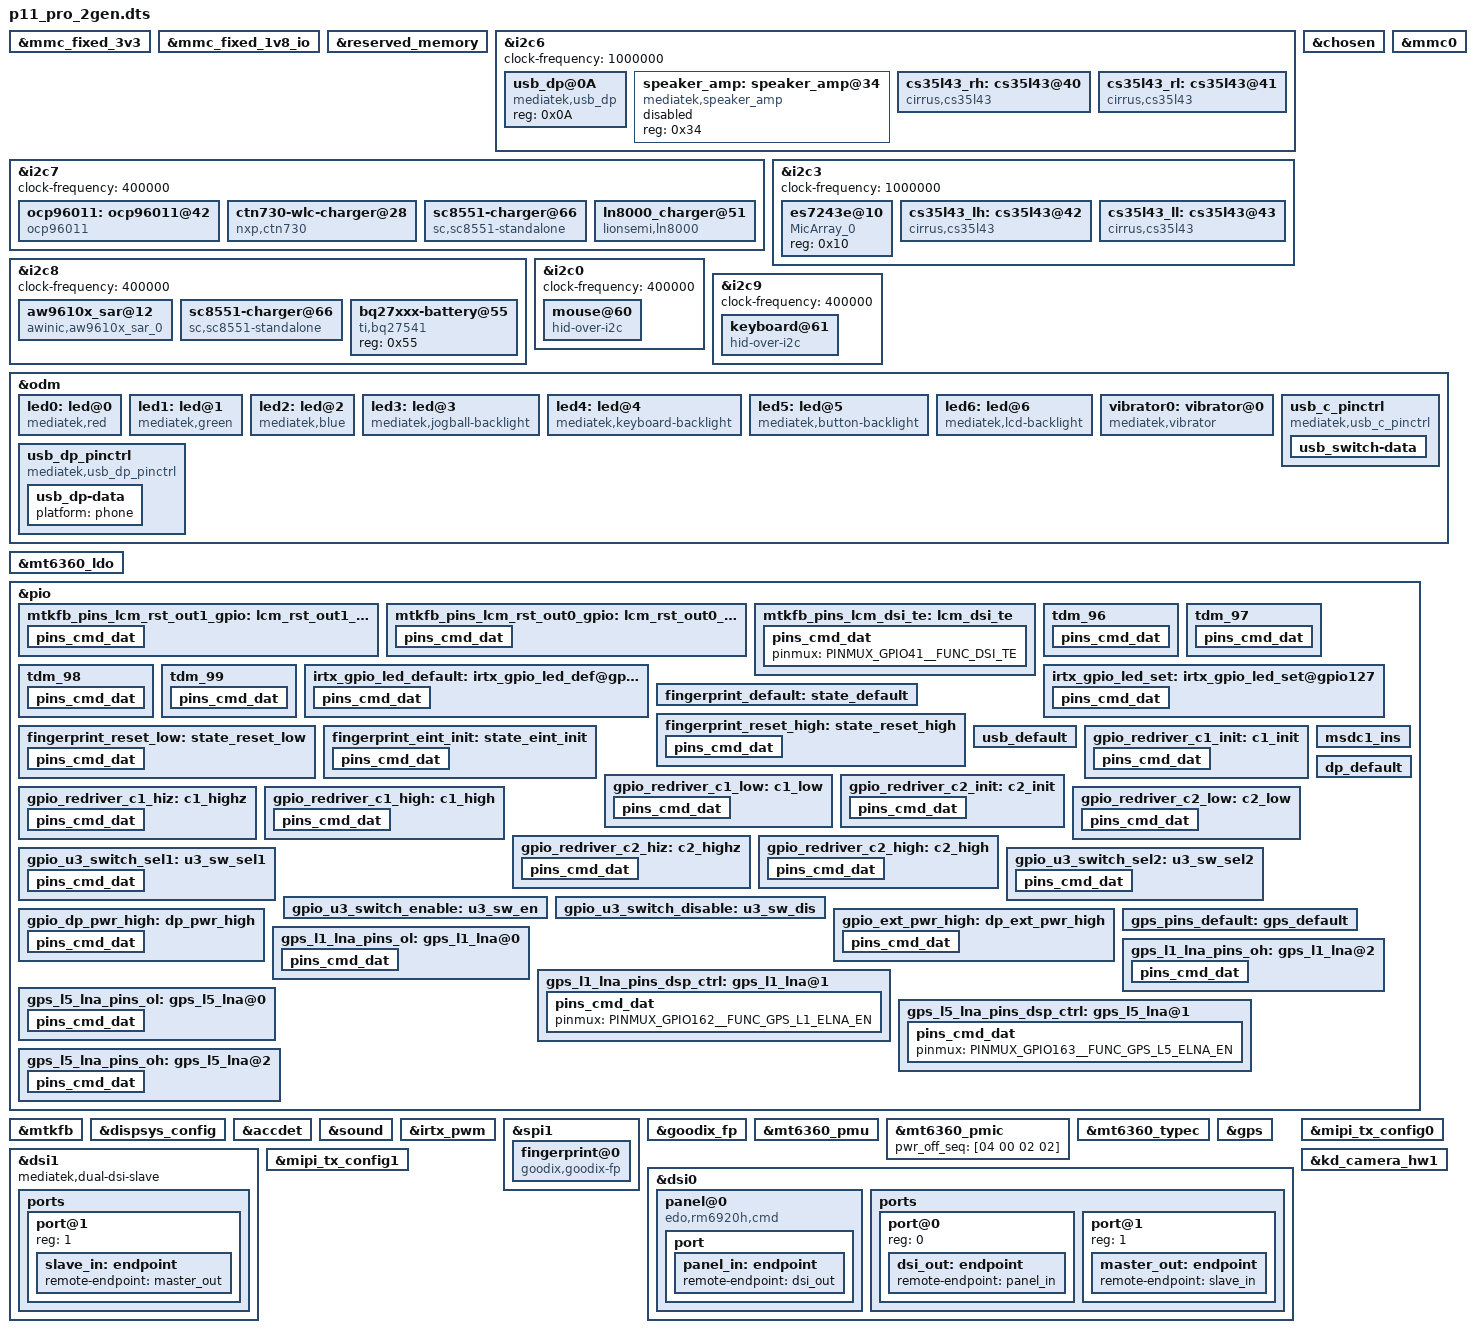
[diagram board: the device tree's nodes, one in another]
/*
 * Mediatek's mt6893 SoC device tree source
 *
 * Copyright (C) 2016 MediaTek Inc.
 *
 * This program is free software; you can redistribute it and/or modify
 * it under the terms of the GNU General Public License version 2 as
 * published by the Free Software Foundation.
 *
 * This program is distributed in the hope that it will be useful,
 * but WITHOUT ANY WARRANTY; without even the implied warranty of
 * MERCHANTABILITY or FITNESS FOR A PARTICULAR PURPOSE.
 * See http://www.gnu.org/licenses/gpl-2.0.html for more details.
 */
/dts-v1/;
/plugin/;
#include <dt-bindings/interrupt-controller/irq.h>
#include <dt-bindings/interrupt-controller/arm-gic.h>
#include <dt-bindings/spmi/spmi.h>
#include <dt-bindings/pinctrl/mt6885-pinfunc.h>

&mmc_fixed_3v3 {
	status = "okay";
	regulator-name = "mmc_power";
	regulator-min-microvolt = <3300000>;
	regulator-max-microvolt = <3300000>;
	enable-active-high;
	regulator-always-on;
};

&mmc_fixed_1v8_io {
	status = "okay";
	regulator-name = "mmc_io";
	regulator-min-microvolt = <1800000>;
	regulator-max-microvolt = <1800000>;
	enable-active-high;
	regulator-always-on;
};

&reserved_memory {
};


&i2c6 {
	clock-frequency = <400000>;
	status = "okay";

	usb_dp@0A {
	compatible = "mediatek,usb_dp";
	reg = <0x0A>;
	status = "okay";
	};
};

&i2c7 {
/*Type-C Analog Audio Switch : OCP96011*/
	ocp96011: ocp96011@42 {
	compatible = "ocp96011";
	reg = <0x42>;
	status = "okay";
	enable-gpio = <&pio 192 0x0>;
	irq-gpio = <&pio 2 0>;
	};

	ctn730-wlc-charger@28 {
	compatible = "nxp,ctn730";
	reg = <0x28>;
	interrupt-gpios = <&pio 15 0x0>;
	rst-gpios = <&pio 133 0x0>;
	boost-5v-gpios = <&pio 185 0x0>;
	enable-gpios = <&pio 193 0x0>;
	status = "okay";
	};
};

&i2c3 {
	status = "okay";
	es7243e@10 {
            compatible = "MicArray_0";
            reg = <0x10>;
	    /*vrf18_adc-supply = <&mt_pmic_vrf18_ldo_reg>;*/
            status = "okay";
    };
};

/* chosen */
&chosen {

	atag,videolfb-fb_base_l = <0x7e020000>;
	atag,videolfb-fb_base_h = <0x0>;
	atag,videolfb-islcmfound = <1>;
	atag,videolfb-islcm_inited = <0>;
	atag,videolfb-fps= <6000>;
	atag,videolfb-vramSize= <0x1be0000>;
	atag,videolfb-lcmname=
		"nt35595_fhd_dsi_cmd_truly_nt50358_drv";
};

&i2c8 {
        clock-frequency = <400000>;

	aw9610x_sar@12 {
		compatible = "awinic,aw9610x_sar_0";
		reg = <0x12>;
		irq-gpio = <&pio 6 0x0>;
		chip_name = "AW96105";
		aw9610x,using-firmware;
		sar-num = < 0 >;
		channel_config = < 1 0 1 0 1>;
		status = "okay";
	};

	sc8551-charger@66{
		compatible = "sc,sc8551-standalone";
		reg = <0x66>;
		sc,sc8551,interrupt_gpios = <&pio 11 0>;
		/*
		sc,sc8551,bat-ovp-disable = <0>;
		sc,sc8551,bat-ocp_disable = <0>;
		sc,sc8551,bat-ovp-alarm-disable = <0>;
		sc,sc8551,bus-ocp-disable = <0>;
		sc,sc8551,bus-ovp-alarm-disable = <0>;
		sc,sc8551,bus-ocp-alarm-disable = <0>;
		sc,sc8551,bat-ucp-alarm-disable = <0>;
		*/
		sc,sc8551,bat-therm-disable = <0>;
		sc,sc8551,bus-therm-disable = <0>;

		sc,sc8551,bat-ovp-threshold = <4500>;
		sc,sc8551,bat-ovp-alarm-threshold = <4450>;
		sc,sc8551,bat-ocp-threshold = <6500>;
		sc,sc8551,bat-ocp-alarm-threshold = <6200>;

		sc,sc8551,bus-ovp-threshold = <12000>;
		sc,sc8551,bus-ovp-alarm-threshold = <11000>;
		sc,sc8551,bus-ocp-threshold = <3500>;
		sc,sc8551,bus-ocp-alarm-threshold = <3200>;

		sc,sc8551,bat-ucp-alarm-threshold = <2000>;

		sc,sc8551,bat-therm-threshold = <0x15>;
		sc,sc8551,bus-therm-threshold = <0x15>;
		sc,sc8551,die-therm-threshold = <125>;

		sc,sc8551,ac-ovp-threshold = <17>;
		sc,sc8551,sense-resistor-mohm = <5>;
	};

	bq27xxx-battery@55 {
		compatible = "ti,bq27541";
		reg = <0x55>;
		status = "okay";
	};
};

&i2c0 {
       //clock-frequency = <1000000>;
	clock-frequency = <400000>;
	status = "okay";
	//as33970@41 {

	//compatible = "syna,as33970";

	mouse@60 {
	compatible = "hid-over-i2c";
	reg = <0x60>;
	vfp-supply = <&mt_pmic_vfp_ldo_reg>;
	mcu_en_gpio = <&pio 185 0>;
	mcu_rst_gpio = <&pio 147 0>;
	mcu_hall_int_gpio = <&pio 159 0>;
	interrupt-parent = <&pio>;
	interrupts = <157 IRQ_TYPE_EDGE_FALLING 157 0>;
	interrupt-names = "keyboard_tp_irq";
	hid-descr-addr =<0x0001>;
	post-power-on-delay-ms= <100>;
	};

};

&i2c7 {
	status="okay";
	clock-frequency = <400000>;

	sc8551-charger@66{
		compatible = "sc,sc8551-standalone";
		reg = <0x66>;
		sc,sc8551,interrupt_gpios = <&pio 11 0>;
		/*
		sc,sc8551,bat-ovp-disable = <0>;
		sc,sc8551,bat-ocp_disable = <0>;
		sc,sc8551,bat-ovp-alarm-disable = <0>;
		sc,sc8551,bus-ocp-disable = <0>;
		sc,sc8551,bus-ovp-alarm-disable = <0>;
		sc,sc8551,bus-ocp-alarm-disable = <0>;
		sc,sc8551,bat-ucp-alarm-disable = <0>;
		*/
		sc,sc8551,bat-therm-disable = <0>;
		sc,sc8551,bus-therm-disable = <0>;

		sc,sc8551,bat-ovp-threshold = <4500>;
		sc,sc8551,bat-ovp-alarm-threshold = <4450>;
		sc,sc8551,bat-ocp-threshold = <6500>;
		sc,sc8551,bat-ocp-alarm-threshold = <6200>;

		sc,sc8551,bus-ovp-threshold = <12000>;
		sc,sc8551,bus-ovp-alarm-threshold = <11000>;
		sc,sc8551,bus-ocp-threshold = <3500>;
		sc,sc8551,bus-ocp-alarm-threshold = <3200>;

		sc,sc8551,bat-ucp-alarm-threshold = <2000>;

		sc,sc8551,bat-therm-threshold = <0x15>;
		sc,sc8551,bus-therm-threshold = <0x15>;
		sc,sc8551,die-therm-threshold = <125>;

		sc,sc8551,ac-ovp-threshold = <17>;
		sc,sc8551,sense-resistor-mohm = <5>;
	};

	ln8000_charger@51 {
		compatible = "lionsemi,ln8000";
		reg = <0x51>;

		/* INT-pin irq description for rpi-4-b */
		ln8000,irq_gpio = <&pio 11 0>;

		/* device configuration */
		ln8000_charger,bat-ovp-threshold = <4550>;
		ln8000_charger,bat-ovp-alarm-threshold = <4525>;
		ln8000_charger,bus-ovp-threshold = <13000>;
		ln8000_charger,bus-ovp-alarm-threshold = <11000>;
		ln8000_charger,bus-ocp-threshold = <3750>;
		ln8000_charger,bus-ocp-alarm-threshold = <3500>;
		ln8000_charger,ntc-alarm-cfg  = <226>;
		/* used external OVP control IC */
		ln8000_charger,ext_ovp_ctrl = <0>;
		/* protection enable/disable flags
		*   vbat-ovp-disable
		*   iin-ocp-disable
		*   tbus-mon-disable
		*   tbat-mon-disable
		*   tdie-prot-disable
		*/
		ln8000_charger,tdie-prot-disable;
		ln8000_charger,tbus-mon-disable;
		ln8000_charger,tbat-mon-disable;
		};
};

&i2c9 {
	status="okay";
	clock-frequency = <400000>;
	keyboard@61 {
		 compatible = "hid-over-i2c";
		 reg = <0x61>;
		 vfp-supply = <&mt_pmic_vfp_ldo_reg>;
		 interrupt-parent = <&pio>;
		 interrupts = <156 IRQ_TYPE_EDGE_FALLING 156 0>;
		 interrupt-names = "keyboard_kb_irq";
		 hid-descr-addr =<0x0001>;
		 mcu_en_gpio = <&pio 185 0>;
		 mcu_rst_gpio = <&pio 147 0>;
		 mcu_hall_int_gpio = <&pio 159 0>;
		 pogo_sw_en_gpio = <&pio 188 0>;
		 post-power-on-delay-ms= <100>;
		 status = "okay";
	};
};

&mmc0 {
	status = "okay";
	/* pinctrl-names = "default", "state_uhs"; */
	/* pinctrl-0 = <&mmc0_pins_default>; */
	/* pinctrl-1 = <&mmc0_pins_uhs>; */
	bus-width = <8>;
	max-frequency = <5000000>;
	cap-mmc-highspeed;
	no-sdio;
	no-sd;
	vmmc-supply = <&mmc_fixed_3v3>;
	vqmmc-supply = <&mmc_fixed_1v8_io>;
	non-removable;
};

&odm {
	led0:led@0 {
		compatible = "mediatek,red";
		led_mode = <0>;
		data = <1>;
		pwm_config = <0 0 0 0 0>;
	};
	led1:led@1 {
		compatible = "mediatek,green";
		led_mode = <0>;
		data = <1>;
		pwm_config = <0 0 0 0 0>;
	};
	led2:led@2 {
		compatible = "mediatek,blue";
		led_mode = <0>;
		data = <1>;
		pwm_config = <0 0 0 0 0>;
	};
	led3:led@3 {
		compatible = "mediatek,jogball-backlight";
		led_mode = <0>;
		data = <1>;
		pwm_config = <0 0 0 0 0>;
	};
	led4:led@4 {
		compatible = "mediatek,keyboard-backlight";
		led_mode = <0>;
		data = <1>;
		pwm_config = <0 0 0 0 0>;
	};
	led5:led@5 {
		compatible = "mediatek,button-backlight";
		led_mode = <0>;
		data = <1>;
		pwm_config = <0 0 0 0 0>;
	};
	led6:led@6 {
		compatible = "mediatek,lcd-backlight";
		led_mode = <4>;
		data = <1>;
		pwm_config = <0 1 0 0 0>;
	};
	vibrator0:vibrator@0 {
		compatible = "mediatek,vibrator";
		vib_timer = <25>;
		vib_limit = <9>;
		vib_vol= <11>;
	};
	usb_c_pinctrl:usb_c_pinctrl {
		compatible = "mediatek,usb_c_pinctrl";
	};
	usb_dp_pinctrl:usb_dp_pinctrl {
		compatible = "mediatek,usb_dp_pinctrl";
	};
};

/* DISPSYS GPIO standardization */
&mt6360_ldo {
	sdcard_hlact = <1>;
	sdcard_det_en = <0>;
};
&pio {
	mtkfb_pins_lcm_rst_out1_gpio: lcm_rst_out1_gpio {
		pins_cmd_dat {
			pinmux = <PINMUX_GPIO42__FUNC_GPIO42>;
			slew-rate = <1>;
			output-high;
		};
	};

	mtkfb_pins_lcm_rst_out0_gpio: lcm_rst_out0_gpio {
		pins_cmd_dat {
			pinmux = <PINMUX_GPIO42__FUNC_GPIO42>;
			slew-rate = <1>;
			output-low;
		};
	};

	mtkfb_pins_lcm_dsi_te: lcm_dsi_te {
		pins_cmd_dat {
			pinmux = <PINMUX_GPIO41__FUNC_DSI_TE>;
		};
	};
};

&mtkfb {
	pinctrl-names = 
		"lcm_rst_out1_gpio", "lcm_rst_out0_gpio",
		"mode_te_te";
	pinctrl-0 = <&mtkfb_pins_lcm_rst_out1_gpio>;
	pinctrl-1 = <&mtkfb_pins_lcm_rst_out0_gpio>;
	pinctrl-2 = <&mtkfb_pins_lcm_dsi_te>;
	status = "okay";
};

&dispsys_config {
	pinctrl-names =
		"lcm_rst_out1_gpio", "lcm_rst_out0_gpio",
		"mode_te_te";
	pinctrl-0 = <&mtkfb_pins_lcm_rst_out1_gpio>;
	pinctrl-1 = <&mtkfb_pins_lcm_rst_out0_gpio>;
	pinctrl-2 = <&mtkfb_pins_lcm_dsi_te>;
	status = "okay";
};
/* DISPSYS GPIO standardization end */

/* accdet start */
&accdet {
	/* accdet micbias voltage: 0x09:2.85v 0x08:2.8v 0x07,
	 * 2.7v;0x05,2.5v;0x02,1.9v
	 */
	accdet-mic-vol = <8>;
	/* accdet pwm_width, pwm_thresh, fall_delay, rise_delay
	 * debounce0, debounce1, debounce3, debounce4
	 * eint pwm_width, eint pwm_thresh
	 * eint deb(debounce0, debounce1, debounce2, debounce3), inv_debounce
	 */
	headset-mode-setting = <0x500 0x500 1 0x1f0
				0x800 0x800 0x20 0x44
				0x4 0x1
				0x5 0x3 0x3 0x5 0xe>;
	accdet-plugout-debounce = <1>;
	/*1:ACC mode, 2:low cost without in bias, 6:low cost with in bias*/
	accdet-mic-mode = <2>;
	/*0--MD_MAX--UP_MAX--DW_MAX*/
	headset-three-key-threshold = <0 80 220 400>;
	headset-three-key-threshold-CDD = <0 121 192 600>;
	/*0--MD_MAX--VOICE_MAX--UP_MAX--DW_MAX*/
	headset-four-key-threshold = <0 58 121 192 400>;

	/* select VTH to 2v and 500k, use internal resitance */
	eint_use_ext_res = <0>;
	status = "okay";
};
/* accdet end */
&pio {

	tdm_96: tdm_96{
			pins_cmd_dat {
			pinmux = <PINMUX_GPIO96__FUNC_TDM_LRCK>;
			
			drive-strength=<7>;
		};
	};
	tdm_97: tdm_97{
			pins_cmd_dat {
			pinmux = <PINMUX_GPIO97__FUNC_TDM_BCK>;
			drive-strength=<7>;
		};
	};
	tdm_98: tdm_98{
			pins_cmd_dat {
			pinmux = <PINMUX_GPIO98__FUNC_TDM_MCK>;
			drive-strength=<7>;
		};
	};
	tdm_99: tdm_99{
			pins_cmd_dat {
			pinmux = <PINMUX_GPIO99__FUNC_TDM_DATA0>;
			drive-strength=<7>;
		};
	};
};
&i2c6 {
	clock-frequency = <1000000>;
	status = "okay";
	speaker_amp: speaker_amp@34 {
		compatible = "mediatek,speaker_amp";
		#sound-dai-cells = <0>;
		reg = <0x34>;
		status = "disable";
	};
	cs35l43_rh: cs35l43@40 {
		#sound-dai-cells = <1>;
		compatible = "cirrus,cs35l43";
		reg = <0x40>;
		/* NFC header pin 16 */
		
		interrupt-parent = <&pio>;
		interrupts = <18 IRQ_TYPE_LEVEL_LOW 18 0>;
		reset-gpios = <&pio 126 0>;
		cirrus,dsp-part-name= "spk1-cs35l43";
        //cirrus,boost-ctl-millivolt=<3200>;
      cirrus,boost-peak-milliamp=<3200>;
        cirrus,vpbr-enable =<1>;
        cirrus,vpbr-atk-vol=<2>;
        cirrus,vpbr-max-att=<6>;
        cirrus,vpbr-thld=<0x15>;
		//pinctrl-names = "default";
		//pinctrl-0 = <&amp_rh_irq>,<&amp_rh_reset>;
		status = "okay";
	};
	cs35l43_rl: cs35l43@41 {
		compatible = "cirrus,cs35l43";
		reg = <0x41>;	
		interrupt-parent = <&pio>;
		interrupts = <14 IRQ_TYPE_LEVEL_LOW 14 0>;
		reset-gpios = <&pio 127 0>;
		cirrus,dsp-part-name= "spk2-cs35l43";
        //cirrus,boost-ctl-millivolt=<3200>;
      cirrus,boost-peak-milliamp=<3200>;
        cirrus,vpbr-enable =<1>;
        cirrus,vpbr-atk-vol=<2>;
        cirrus,vpbr-max-att=<6>;
        cirrus,vpbr-thld=<0x15>;
		//pinctrl-names = "default";
		//pinctrl-0 = <&amp_rl_irq>,<&amp_rl_reset>;
		status = "okay";
	};
};

&i2c3 {
	clock-frequency = <1000000>;
	status = "okay";
	cs35l43_lh: cs35l43@42 {
		compatible = "cirrus,cs35l43";
		reg = <0x42>;

		reset-gpios = <&pio 28 0>;
		interrupt-parent = <&pio>;
		interrupts = <13 IRQ_TYPE_LEVEL_LOW 13 0>;
		cirrus,dsp-part-name= "spk3-cs35l43";
        //cirrus,boost-ctl-millivolt=<3200>;
      cirrus,boost-peak-milliamp=<3200>;
        cirrus,vpbr-enable =<1>;
        cirrus,vpbr-atk-vol=<2>;
        cirrus,vpbr-max-att=<6>;
        cirrus,vpbr-thld=<0x15>;
		//pinctrl-names = "default";
		//pinctrl-0 = <&amp_lh_irq>, <&amp_lh_reset>;
		status = "okay";
	};
	cs35l43_ll: cs35l43@43 {
		compatible = "cirrus,cs35l43";
		reg = <0x43>;

		reset-gpios = <&pio 30 0>;
		interrupt-parent = <&pio>;
		interrupts = <5 IRQ_TYPE_LEVEL_LOW 5 0>;
		cirrus,dsp-part-name= "spk4-cs35l43";
        //cirrus,boost-ctl-millivolt=<3200>;
      cirrus,boost-peak-milliamp=<3200>;
        cirrus,vpbr-enable =<1>;
        cirrus,vpbr-atk-vol=<2>;
        cirrus,vpbr-max-att=<6>;
        cirrus,vpbr-thld=<0x15>;
		//pinctrl-names = "default";
		//pinctrl-0 = <&amp_ll_irq>, <&amp_ll_reset>;
		status = "okay";
	};
};

&sound{
	pinctrl-names="default";
	pinctrl-0 = <&tdm_96>, <&tdm_97>, <&tdm_98>,<&tdm_99>;
	cirrus,prince-max-devs = <4>;
	cirrus,prince-devs = <&cs35l43_rh>, <&cs35l43_rl>, <&cs35l43_lh>, <&cs35l43_ll>;
	cirrus,prince-dev-prefix = "SPK1", "SPK2", "SPK3", "SPK4";
};
/* IRTX GPIO Start */
&irtx_pwm {
	pinctrl-names = "irtx_gpio_led_default", "irtx_gpio_led_set";
	pinctrl-0 = <&irtx_gpio_led_default>;
	pinctrl-1 = <&irtx_gpio_led_set>;
	status = "okay";
};
&pio {
	/* IRTX GPIO Settings -Start */
	/* default: GPIO0, output, high */
	irtx_gpio_led_default:irtx_gpio_led_def@gpio127 {
		pins_cmd_dat {
			pinmux = <PINMUX_GPIO127__FUNC_GPIO127>;
			slew-rate = <1>;
			bias-disable;
			output-low;
			input-schmitt-enable = <0>;
		};
	};

	irtx_gpio_led_set:irtx_gpio_led_set@gpio127 {
		pins_cmd_dat {
			pinmux = <PINMUX_GPIO127__FUNC_PWM_3>;
			slew-rate = <1>;
			output-high;
		};
	};
}; /* IRTX GPIO Settings -End */

/* FINGERPRINT start */
&spi1 {
	#address-cells = <1>;
	#size-cells = <0>;
	fingerprint@0 {
		compatible = "goodix,goodix-fp";
		reg = <0>;
		spi-max-frequency = <8000000>;
		netlink-event = <30>;
		vfp-supply = <&mt_pmic_vfp_ldo_reg>;
		power-type = <1>;
		status = "okay";
	};
};

&goodix_fp {
	pinctrl-names = "default", "reset_high", "reset_low", "eint_init";
	pinctrl-0 = <&fingerprint_default>;
	pinctrl-1 = <&fingerprint_reset_high>;
	pinctrl-2 = <&fingerprint_reset_low>;
	pinctrl-3 = <&fingerprint_eint_init>;
	interrupt-parent = <&pio>;
	interrupts = <15 IRQ_TYPE_EDGE_RISING 15 0>;
	status = "okay";
};

&pio {
	fingerprint_default: state_default {
	};
	fingerprint_reset_high: state_reset_high {
		pins_cmd_dat {
			pinmux = <PINMUX_GPIO14__FUNC_GPIO14>;
			slew-rate = <1>;
			output-high;
		};
	};
	fingerprint_reset_low: state_reset_low {
		pins_cmd_dat {
			pinmux = <PINMUX_GPIO14__FUNC_GPIO14>;
			slew-rate = <1>;
			output-low;
		};
	};
	fingerprint_eint_init: state_eint_init {
		pins_cmd_dat {
			pinmux = <PINMUX_GPIO15__FUNC_GPIO15>;
			slew-rate = <0>;
			bias-pull-up = <MTK_PUPD_SET_R1R0_10>;
			input-schmitt-enable;
		};
	};
};
/* FINGERPRINT end */

&mt6360_pmu {
	mt6360,intr_gpio_num = <24>; /* direct defined GPIO num */
	mt6360,intr_gpio = <&pio 24 0x0>;
};

&mt6360_pmic {
	pwr_off_seq = [04 00 02 02];
};

&mt6360_typec {
	mt6360pd,intr_gpio_num = <25>; /* direct defined GPIO num */
	mt6360pd,intr_gpio = <&pio 25 0x0>;
};

/* USB SWITCH GPIO start */
&pio {
	usb_default: usb_default {
	};

	gpio_redriver_c1_init: c1_init {
		pins_cmd_dat {
			pinmux = <PINMUX_GPIO191__FUNC_GPIO191>;
			slew-rate = <1>;
			output-low;
		};
	};

	gpio_redriver_c1_low: c1_low {
		pins_cmd_dat {
			pinmux = <PINMUX_GPIO191__FUNC_GPIO191>;
			slew-rate = <1>;
			output-low;
		};
	};

	gpio_redriver_c1_hiz: c1_highz {
		pins_cmd_dat {
			pinmux = <PINMUX_GPIO191__FUNC_GPIO191>;
			slew-rate= <0>;
			bias-disable;
		};
	};

	gpio_redriver_c1_high: c1_high {
		pins_cmd_dat {
			pinmux = <PINMUX_GPIO191__FUNC_GPIO191>;
			slew-rate = <1>;
			output-high;
		};
	};

	gpio_redriver_c2_init: c2_init {
		pins_cmd_dat {
	//		pinmux = <PINMUX_GPIO189__FUNC_GPIO189>;
			slew-rate = <1>;
			output-low;
		};
	};

	gpio_redriver_c2_low: c2_low {
		pins_cmd_dat {
	//		pinmux = <PINMUX_GPIO189__FUNC_GPIO189>;
			slew-rate = <1>;
			output-low;
		};
	};

	gpio_redriver_c2_hiz: c2_highz {
		pins_cmd_dat {
	//		pinmux = <PINMUX_GPIO189__FUNC_GPIO189>;
			slew-rate= <0>;
			bias-disable;
		};
	};

	gpio_redriver_c2_high: c2_high {
		pins_cmd_dat {
	//		pinmux = <PINMUX_GPIO189__FUNC_GPIO189>;
			slew-rate = <1>;
			output-high;
		};
	};

	gpio_u3_switch_sel1: u3_sw_sel1 {
		pins_cmd_dat {
	//		pinmux = <PINMUX_GPIO111__FUNC_GPIO111>;
			slew-rate = <1>;
			output-low;
		};
	};

	gpio_u3_switch_sel2: u3_sw_sel2 {
		pins_cmd_dat {
	//		pinmux = <PINMUX_GPIO111__FUNC_GPIO111>;
			slew-rate = <1>;
			output-high;
		};
	};

	gpio_u3_switch_enable: u3_sw_en {
	};

	gpio_u3_switch_disable: u3_sw_dis {
	};
	msdc1_ins: msdc1_ins{
	};
};

&usb_c_pinctrl {
	pinctrl-names = "usb_default",
		"redrv_c1_init",
		"redrv_c1_low",
		"redrv_c1_hiz",
		"redrv_c1_high",
		"redrv_c2_init",
		"redrv_c2_low",
		"redrv_c2_hiz",
		"redrv_c2_high",
		"switch_sel1",
		"switch_sel2",
		"switch_enable",
		"switch_disable";

	pinctrl-0 = <&usb_default>;
	pinctrl-1 = <&gpio_redriver_c1_init>;
	pinctrl-2 = <&gpio_redriver_c1_low>;
	pinctrl-3 = <&gpio_redriver_c1_hiz>;
	pinctrl-4 = <&gpio_redriver_c1_high>;
	pinctrl-5 = <&gpio_redriver_c2_init>;
	pinctrl-6 = <&gpio_redriver_c2_low>;
	pinctrl-7 = <&gpio_redriver_c2_hiz>;
	pinctrl-8 = <&gpio_redriver_c2_high>;
	pinctrl-9 = <&gpio_u3_switch_sel1>;
	pinctrl-10 = <&gpio_u3_switch_sel2>;
	pinctrl-11 = <&gpio_u3_switch_enable>;
	pinctrl-12 = <&gpio_u3_switch_disable>;
	status = "okay";

	usb_switch-data {
		en_pin_num = <0>;
		en_pin_val = <0>;
//		sel_pin_num = <111>;
		sel_pin_val = <1>;
		c1_pin_num = <191>;
		c1_pin_val = <2>;
//		c2_pin_num = <189>;
		c2_pin_val = <1>;
	};
};
/* USB SWITCH GPIO end */

/* USB DP SWITCH GPIO start */
&pio {
	dp_default: dp_default {
	};

	gpio_dp_pwr_high: dp_pwr_high {
		pins_cmd_dat {
			pinmux = <PINMUX_GPIO191__FUNC_GPIO191>;
			slew-rate = <1>;
			output-high;
		};
	};

	gpio_ext_pwr_high: dp_ext_pwr_high {
		pins_cmd_dat {
			pinmux = <PINMUX_GPIO191__FUNC_GPIO191>;
			slew-rate = <1>;
			output-low;
		};
	};
};

&usb_dp_pinctrl {
	pinctrl-names = "dp_default",
		"dp_pwr_high",
		"dp_ext_pwr_high";

	pinctrl-0 = <&dp_default>;
	pinctrl-1 = <&gpio_dp_pwr_high>;
	pinctrl-2 = <&gpio_ext_pwr_high>;
	status = "okay";

	usb_dp-data {
		platform = "phone";
	};
};
/* USB DP SWITCH GPIO end */

/* GPS GPIO standardization start */
&pio {
	gps_pins_default: gps_default {
	};

	gps_l1_lna_pins_ol: gps_l1_lna@0 {
		pins_cmd_dat {
			pinmux = <PINMUX_GPIO162__FUNC_GPIO162>;
			output-low;
		};
	};
	gps_l1_lna_pins_dsp_ctrl: gps_l1_lna@1 {
		pins_cmd_dat {
			pinmux = <PINMUX_GPIO162__FUNC_GPS_L1_ELNA_EN>;
		};
	};
	gps_l1_lna_pins_oh: gps_l1_lna@2 {
		pins_cmd_dat {
			pinmux = <PINMUX_GPIO162__FUNC_GPIO162>;
			output-high;
		};
	};

	gps_l5_lna_pins_ol: gps_l5_lna@0 {
		pins_cmd_dat {
			pinmux = <PINMUX_GPIO163__FUNC_GPIO163>;
			output-low;
		};
	};
	gps_l5_lna_pins_dsp_ctrl: gps_l5_lna@1 {
		pins_cmd_dat {
			pinmux = <PINMUX_GPIO163__FUNC_GPS_L5_ELNA_EN>;
		};
	};
	gps_l5_lna_pins_oh: gps_l5_lna@2 {
		pins_cmd_dat {
			pinmux = <PINMUX_GPIO163__FUNC_GPIO163>;
			output-high;
		};
	};
};

&gps {
	pinctrl-names = "default",
		"gps_l1_lna_disable",
		"gps_l1_lna_dsp_ctrl",
		"gps_l1_lna_enable",
		"gps_l5_lna_disable",
		"gps_l5_lna_dsp_ctrl",
		"gps_l5_lna_enable";
	pinctrl-0 = <&gps_pins_default>;
	pinctrl-1 = <&gps_l1_lna_pins_ol>;
	pinctrl-2 = <&gps_l1_lna_pins_dsp_ctrl>;
	pinctrl-3 = <&gps_l1_lna_pins_oh>;
	pinctrl-4 = <&gps_l5_lna_pins_ol>;
	pinctrl-5 = <&gps_l5_lna_pins_dsp_ctrl>;
	pinctrl-6 = <&gps_l5_lna_pins_oh>;
	status = "okay";
};
/* GPS GPIO standardization end */

&dsi0 {
	status = "okay";
	#address-cells = <1>;
	#size-cells = <0>;
	panel@0 {
		compatible = "edo,rm6920h,cmd";
		reg = <0>;
		reset-gpios = <&pio 42 0>;
		reg-vddi-supply = <&mt_pmic_vm18_ldo_reg>;
		reg-vci-supply = <&mt_pmic_vfe28_ldo_reg>;
		reg-vci1-supply = <&mt_pmic_vtp_ldo_reg>;
		pinctrl-names = "default";
		port {
			panel_in: endpoint {
				remote-endpoint = <&dsi_out>;
			};
		};
	};
	ports {
		port@0 {
			reg = <0>;
			dsi_out: endpoint {
				remote-endpoint = <&panel_in>;
			};
		};
		port@1 {
			reg = <1>;
			master_out: endpoint {
				remote-endpoint = <&slave_in>;
			};
		};
	};
};

&dsi1{
	mediatek,dual-dsi-slave;
	status = "okay";
	ports {
		port@1 {
			reg = <1>;
			slave_in: endpoint {
				remote-endpoint = <&master_out>;
			};
		};
	};
};

&mipi_tx_config0{
	status = "okay";
};

&mipi_tx_config1{
	status = "okay";
};

/* CAMERA specify sensor */
&kd_camera_hw1 {
	cam2_enable_sensor = "imx586_mipi_raw s5k3m5sx_mipi_raw";
	cam4_enable_sensor = "imx586_mipi_raw imx481_mipi_raw";
};
/* CAMERA specify sensor end */

#include "mediatek/cust_mt6893_touch.dtsi"
#include "mediatek/cust_mt6885_camera.dtsi"
#include "mediatek/cust_mt8797_hall.dtsi"
#include <p11_pro_2gen/cust.dtsi>
/*End of this file, DO NOT ADD ANYTHING HERE*/
